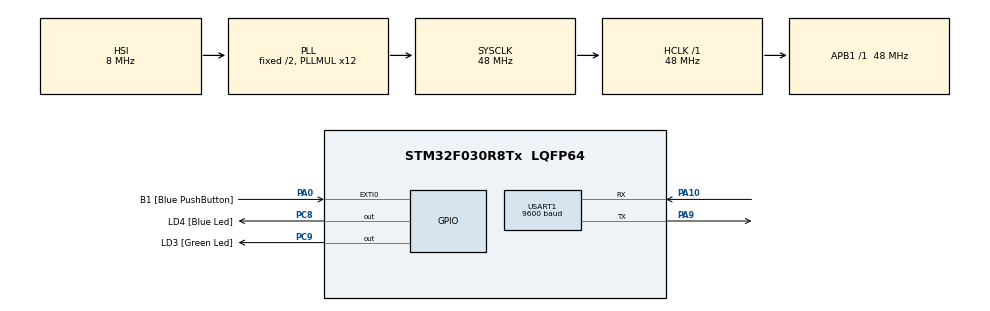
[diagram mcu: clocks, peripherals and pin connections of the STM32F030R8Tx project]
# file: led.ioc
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Mcu.Family=STM32F0
PA10.Mode=Asynchronous
PC9.GPIO_Label=LD3 [Green Led]
USART1.BaudRate=9600
PA14.GPIO_Label=SWCLK
PA0.GPIO_Label=B1 [Blue PushButton]
PC8.Signal=GPIO_Output
RCC.SYSCLKSource=RCC_SYSCLKSOURCE_PLLCLK
ProjectManager.StackSize=0x400
PC8.GPIO_Label=LD4 [Blue Led]
USART1.VirtualMode-Asynchronous=VM_ASYNC
PA13.Signal=SYS_SWDIO
PA9.Mode=Asynchronous
ProjectManager.TargetToolchain=STM32CubeIDE
RCC.HCLKFreq_Value=48000000
TIM3.Period=499
PA9.Signal=USART1_TX
RCC.AHBFreq_Value=48000000
board=STM32F0308-DISCO
RCC.PLLMUL=RCC_PLL_MUL12
NVIC.TIM3_IRQn=true\:0\:0\:false\:false\:true\:true\:true
PA14.Mode=Serial_Wire
PA0.GPIO_ModeDefaultEXTI=GPIO_MODE_EVT_RISING
TIM3.Prescaler=48000
PA13.Mode=Serial_Wire
Mcu.Name=STM32F030R8Tx
PA13.GPIO_Label=SWDIO
PA0.Signal=GPXTI0
RCC.SYSCLKFreq_VALUE=48000000
Mcu.Package=LQFP64
PA10.Signal=USART1_RX
PA14.Signal=SYS_SWCLK
ProjectManager.HeapSize=0x200
RCC.APB1TimFreq_Value=48000000
PC9.Signal=GPIO_Output
RCC.APB1Freq_Value=48000000
VP_TIM3_VS_ClockSourceINT.Mode=Internal

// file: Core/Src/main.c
/* USER CODE BEGIN Header */
/**
  ******************************************************************************
  * @file           : main.c
  * @brief          : Main program body
  ******************************************************************************
  * @attention
  *
  * <h2><center>&copy; Copyright (c) 2021 STMicroelectronics.
  * All rights reserved.</center></h2>
  *
  * This software component is licensed by ST under BSD 3-Clause license,
  * the "License"; You may not use this file except in compliance with the
  * License. You may obtain a copy of the License at:
  *                        opensource.org/licenses/BSD-3-Clause
  *
  ******************************************************************************
  */
/* USER CODE END Header */
#include "main.h"

TIM_HandleTypeDef htim3;

UART_HandleTypeDef huart1;

/* USER CODE BEGIN PV */
void HAL_TIM_PeriodElapsedCallback(TIM_HandleTypeDef *htim)
{
    if (htim->Instance==TIM3) //check if the interrupt comes from TIM3
        {
        //HAL_GPIO_TogglePin(GPIOC, LD4_Pin);
        HAL_UART_Transmit(&huart1, (uint8_t *)"hello", 5, 1000);
        }
}
/* USER CODE END PV */

void SystemClock_Config(void);
static void MX_GPIO_Init(void);
static void MX_TIM3_Init(void);
static void MX_USART1_UART_Init(void);

int main(void)
{

  /* MCU Configuration--------------------------------------------------------*/

  /* Reset of all peripherals, Initializes the Flash interface and the Systick. */
  HAL_Init();

  /* Configure the system clock */
  SystemClock_Config();

  /* Initialize all configured peripherals */
  MX_GPIO_Init();
  MX_TIM3_Init();
  MX_USART1_UART_Init();
  /* USER CODE BEGIN 2 */
  HAL_GPIO_WritePin(GPIOC, LD3_Pin, GPIO_PIN_SET);

  HAL_PWR_EnableSleepOnExit();
  /* USER CODE END 2 */
  TIM3->SR = 0;
  HAL_TIM_Base_Init(&htim3);
  HAL_TIM_Base_Start_IT(&htim3);
  /* Infinite loop */
  while (1)
  {
	  HAL_GPIO_TogglePin(GPIOC, LD3_Pin);
	  HAL_Delay(1000);
  }
}

void SystemClock_Config(void)
{
  RCC_OscInitTypeDef RCC_OscInitStruct = {0};
  RCC_ClkInitTypeDef RCC_ClkInitStruct = {0};
  RCC_PeriphCLKInitTypeDef PeriphClkInit = {0};

  /** Initializes the RCC Oscillators according to the specified parameters
  * in the RCC_OscInitTypeDef structure.
  */
  RCC_OscInitStruct.OscillatorType = RCC_OSCILLATORTYPE_HSI;
  RCC_OscInitStruct.HSIState = RCC_HSI_ON;
  RCC_OscInitStruct.HSICalibrationValue = RCC_HSICALIBRATION_DEFAULT;
  RCC_OscInitStruct.PLL.PLLState = RCC_PLL_ON;
  RCC_OscInitStruct.PLL.PLLSource = RCC_PLLSOURCE_HSI;
  RCC_OscInitStruct.PLL.PLLMUL = RCC_PLL_MUL12;
  RCC_OscInitStruct.PLL.PREDIV = RCC_PREDIV_DIV1;
  if (HAL_RCC_OscConfig(&RCC_OscInitStruct) != HAL_OK)
  {
    Error_Handler();
  }
  /** Initializes the CPU, AHB and APB buses clocks
  */
  RCC_ClkInitStruct.ClockType = RCC_CLOCKTYPE_HCLK|RCC_CLOCKTYPE_SYSCLK
                              |RCC_CLOCKTYPE_PCLK1;
  RCC_ClkInitStruct.SYSCLKSource = RCC_SYSCLKSOURCE_PLLCLK;
  RCC_ClkInitStruct.AHBCLKDivider = RCC_SYSCLK_DIV1;
  RCC_ClkInitStruct.APB1CLKDivider = RCC_HCLK_DIV1;

  if (HAL_RCC_ClockConfig(&RCC_ClkInitStruct, FLASH_LATENCY_1) != HAL_OK)
  {
    Error_Handler();
  }
  PeriphClkInit.PeriphClockSelection = RCC_PERIPHCLK_USART1;
  PeriphClkInit.Usart1ClockSelection = RCC_USART1CLKSOURCE_PCLK1;
  if (HAL_RCCEx_PeriphCLKConfig(&PeriphClkInit) != HAL_OK)
  {
    Error_Handler();
  }
}

static void MX_TIM3_Init(void)
{

  TIM_ClockConfigTypeDef sClockSourceConfig = {0};
  TIM_MasterConfigTypeDef sMasterConfig = {0};

  htim3.Instance = TIM3;
  htim3.Init.Prescaler = 48000;
  htim3.Init.CounterMode = TIM_COUNTERMODE_UP;
  htim3.Init.Period = 499;
  htim3.Init.ClockDivision = TIM_CLOCKDIVISION_DIV1;
  htim3.Init.AutoReloadPreload = TIM_AUTORELOAD_PRELOAD_DISABLE;
  if (HAL_TIM_Base_Init(&htim3) != HAL_OK)
  {
    Error_Handler();
  }
  sClockSourceConfig.ClockSource = TIM_CLOCKSOURCE_INTERNAL;
  if (HAL_TIM_ConfigClockSource(&htim3, &sClockSourceConfig) != HAL_OK)
  {
    Error_Handler();
  }
  sMasterConfig.MasterOutputTrigger = TIM_TRGO_RESET;
  sMasterConfig.MasterSlaveMode = TIM_MASTERSLAVEMODE_DISABLE;
  if (HAL_TIMEx_MasterConfigSynchronization(&htim3, &sMasterConfig) != HAL_OK)
  {
    Error_Handler();
  }

}

static void MX_USART1_UART_Init(void)
{

  huart1.Instance = USART1;
  huart1.Init.BaudRate = 9600;
  huart1.Init.WordLength = UART_WORDLENGTH_8B;
  huart1.Init.StopBits = UART_STOPBITS_1;
  huart1.Init.Parity = UART_PARITY_NONE;
  huart1.Init.Mode = UART_MODE_TX_RX;
  huart1.Init.HwFlowCtl = UART_HWCONTROL_NONE;
  huart1.Init.OverSampling = UART_OVERSAMPLING_16;
  huart1.Init.OneBitSampling = UART_ONE_BIT_SAMPLE_DISABLE;
  huart1.AdvancedInit.AdvFeatureInit = UART_ADVFEATURE_NO_INIT;
  if (HAL_UART_Init(&huart1) != HAL_OK)
  {
    Error_Handler();
  }

}

static void MX_GPIO_Init(void)
{
  GPIO_InitTypeDef GPIO_InitStruct = {0};

  /* GPIO Ports Clock Enable */
  __HAL_RCC_GPIOA_CLK_ENABLE();
  __HAL_RCC_GPIOC_CLK_ENABLE();

  /*Configure GPIO pin Output Level */
  HAL_GPIO_WritePin(GPIOC, LD4_Pin|LD3_Pin, GPIO_PIN_RESET);

  /*Configure GPIO pin : B1_Pin */
  GPIO_InitStruct.Pin = B1_Pin;
  GPIO_InitStruct.Mode = GPIO_MODE_EVT_RISING;
  GPIO_InitStruct.Pull = GPIO_NOPULL;
  HAL_GPIO_Init(B1_GPIO_Port, &GPIO_InitStruct);

  /*Configure GPIO pins : LD4_Pin LD3_Pin */
  GPIO_InitStruct.Pin = LD4_Pin|LD3_Pin;
  GPIO_InitStruct.Mode = GPIO_MODE_OUTPUT_PP;
  GPIO_InitStruct.Pull = GPIO_NOPULL;
  GPIO_InitStruct.Speed = GPIO_SPEED_FREQ_LOW;
  HAL_GPIO_Init(GPIOC, &GPIO_InitStruct);

}

void Error_Handler(void)
{
  __disable_irq();
  while (1)
  {
  }
}

/************************ (C) COPYRIGHT STMicroelectronics *****END OF FILE****/
